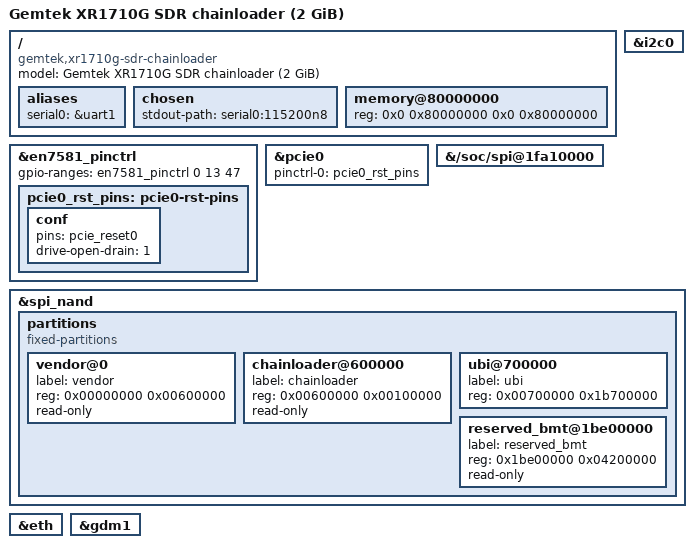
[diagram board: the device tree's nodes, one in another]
// SPDX-License-Identifier: (GPL-2.0-only OR BSD-2-Clause)
/dts-v1/;

/* ATF is installed in the low 2 MiB of DRAM by the vendor boot chain. */
/memreserve/ 0x80000000 0x00200000;

#include <dt-bindings/input/linux-event-codes.h>
#include <dt-bindings/gpio/gpio.h>
#include "en7581.dtsi"

/ {
	model = "Gemtek XR1710G SDR chainloader (2 GiB)";
	compatible = "gemtek,xr1710g-sdr-chainloader", "gemtek,w1700k-ubi",
		     "airoha,an7581", "airoha,en7581";

	aliases {
		serial0 = &uart1;
	};

	chosen {
		stdout-path = "serial0:115200n8";
	};

	memory@80000000 {
		device_type = "memory";
		reg = <0x0 0x80000000 0x0 0x80000000>;
	};
};

&en7581_pinctrl {
	gpio-ranges = <&en7581_pinctrl 0 13 47>;

	pcie0_rst_pins: pcie0-rst-pins {
		conf {
			pins = "pcie_reset0";
			drive-open-drain = <1>;
		};
	};
};

&pcie0 {
	pinctrl-names = "default";
	pinctrl-0 = <&pcie0_rst_pins>;
	status = "okay";
};

&i2c0 {
	status = "okay";
};

&{/soc/spi@1fa10000} {
	status = "okay";
};

&spi_nand {
	partitions {
		compatible = "fixed-partitions";
		#address-cells = <1>;
		#size-cells = <1>;

		// >>> generated by platform/partitions.py; edit that, not this
		// Raw physical offsets; standard UBI, no vendor BMT.
		vendor@0 {
			label = "vendor";
			reg = <0x00000000 0x00600000>;
			read-only;
		};

		chainloader@600000 {
			label = "chainloader";
			reg = <0x00600000 0x00100000>;
			read-only;
		};

		ubi@700000 {
			label = "ubi";
			reg = <0x00700000 0x1b700000>;
		};

		reserved_bmt@1be00000 {
			label = "reserved_bmt";
			reg = <0x1be00000 0x04200000>;
			read-only;
		};
		// <<< end generated partition table
	};
};

&eth {
	status = "okay";
};

&gdm1 {
	status = "okay";
};
